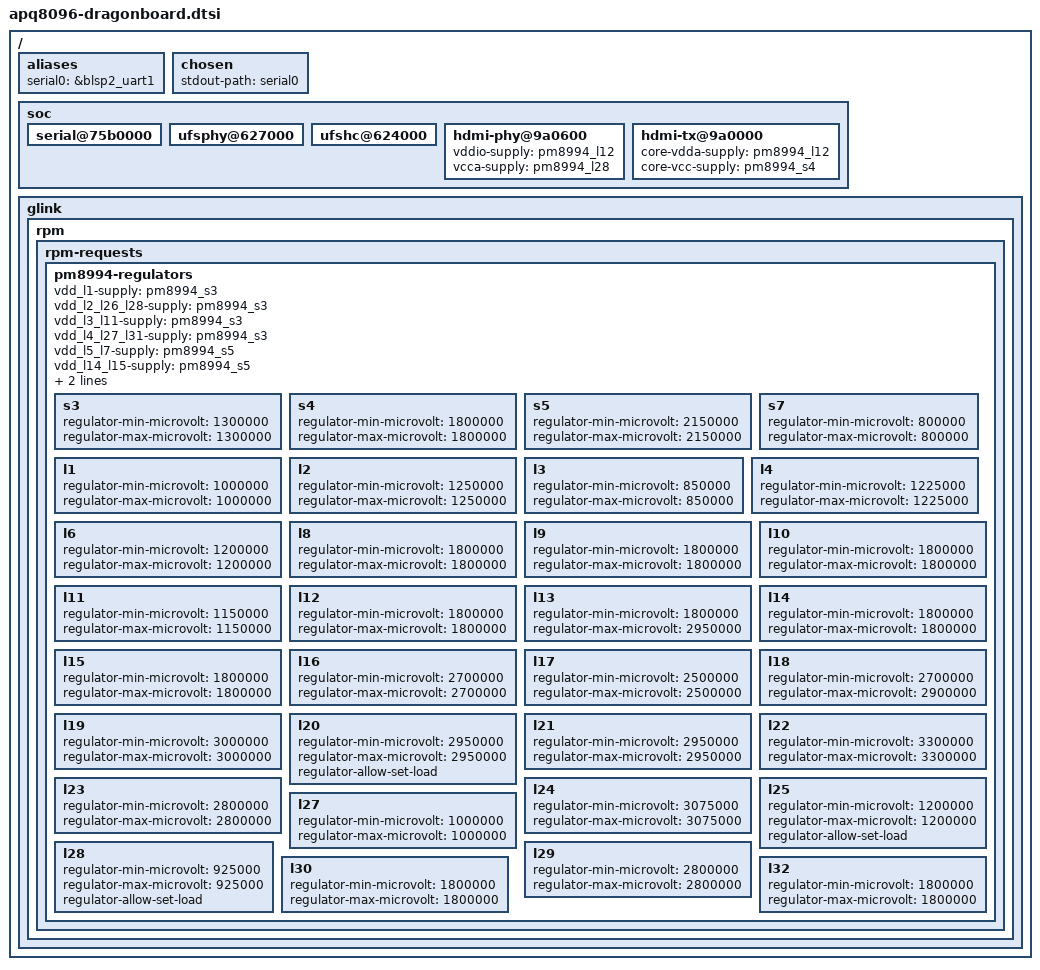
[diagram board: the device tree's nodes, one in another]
/*
 * Copyright (c) 2014-2015, The Linux Foundation. All rights reserved.
 *
 * This program is free software; you can redistribute it and/or modify
 * it under the terms of the GNU General Public License version 2 and
 * only version 2 as published by the Free Software Foundation.
 *
 * This program is distributed in the hope that it will be useful,
 * but WITHOUT ANY WARRANTY; without even the implied warranty of
 * MERCHANTABILITY or FITNESS FOR A PARTICULAR PURPOSE.  See the
 * GNU General Public License for more details.
 */

#include "msm8996.dtsi"
#include "pm8994.dtsi"

/ {
	aliases {
		serial0 = &blsp2_uart1;
	};

	chosen {
		stdout-path = "serial0";
	};

	soc {
		serial@75b0000 {
			status = "okay";
		};

		ufsphy@627000 {
			status = "okay";
		};

		ufshc@624000 {
			status = "okay";
		};

		hdmi-phy@9a0600 {
			status = "okay";

			vddio-supply = <&pm8994_l12>;
			vcca-supply = <&pm8994_l28>;
		};

		hdmi-tx@9a0000 {
			status = "okay";

			core-vdda-supply = <&pm8994_l12>;
			core-vcc-supply = <&pm8994_s4>;
		};
	};

	glink {
		rpm {
			rpm-requests {
				pm8994-regulators {
					vdd_l1-supply = <&pm8994_s3>;
					vdd_l2_l26_l28-supply = <&pm8994_s3>;
					vdd_l3_l11-supply = <&pm8994_s3>;
					vdd_l4_l27_l31-supply = <&pm8994_s3>;
					vdd_l5_l7-supply = <&pm8994_s5>;
					vdd_l14_l15-supply = <&pm8994_s5>;
					vdd_l20_l21-supply = <&pm8994_s5>;
					vdd_l25-supply = <&pm8994_s3>;

					s3 {
						regulator-min-microvolt = <1300000>;
						regulator-max-microvolt = <1300000>;
					};
					s4 {
						regulator-min-microvolt = <1800000>;
						regulator-max-microvolt = <1800000>;
					};
					s5 {
						regulator-min-microvolt = <2150000>;
						regulator-max-microvolt = <2150000>;
					};
					s7 {
						regulator-min-microvolt = <800000>;
						regulator-max-microvolt = <800000>;
					};

					l1 {
						regulator-min-microvolt = <1000000>;
						regulator-max-microvolt = <1000000>;
					};
					l2 {
						regulator-min-microvolt = <1250000>;
						regulator-max-microvolt = <1250000>;
					};
					l3 {
						regulator-min-microvolt = <850000>;
						regulator-max-microvolt = <850000>;
					};
					l4 {
						regulator-min-microvolt = <1225000>;
						regulator-max-microvolt = <1225000>;
					};
					l6 {
						regulator-min-microvolt = <1200000>;
						regulator-max-microvolt = <1200000>;
					};
					l8 {
						regulator-min-microvolt = <1800000>;
						regulator-max-microvolt = <1800000>;
					};
					l9 {
						regulator-min-microvolt = <1800000>;
						regulator-max-microvolt = <1800000>;
					};
					l10 {
						regulator-min-microvolt = <1800000>;
						regulator-max-microvolt = <1800000>;
					};
					l11 {
						regulator-min-microvolt = <1150000>;
						regulator-max-microvolt = <1150000>;
					};
					l12 {
						regulator-min-microvolt = <1800000>;
						regulator-max-microvolt = <1800000>;
					};
					l13 {
						regulator-min-microvolt = <1800000>;
						regulator-max-microvolt = <2950000>;
					};
					l14 {
						regulator-min-microvolt = <1800000>;
						regulator-max-microvolt = <1800000>;
					};
					l15 {
						regulator-min-microvolt = <1800000>;
						regulator-max-microvolt = <1800000>;
					};
					l16 {
						regulator-min-microvolt = <2700000>;
						regulator-max-microvolt = <2700000>;
					};
					l17 {
						regulator-min-microvolt = <2500000>;
						regulator-max-microvolt = <2500000>;
					};
					l18 {
						regulator-min-microvolt = <2700000>;
						regulator-max-microvolt = <2900000>;
					};
					l19 {
						regulator-min-microvolt = <3000000>;
						regulator-max-microvolt = <3000000>;
					};
					l20 {
						regulator-min-microvolt = <2950000>;
						regulator-max-microvolt = <2950000>;
						regulator-allow-set-load;
					};
					l21 {
						regulator-min-microvolt = <2950000>;
						regulator-max-microvolt = <2950000>;
					};
					l22 {
						regulator-min-microvolt = <3300000>;
						regulator-max-microvolt = <3300000>;
					};
					l23 {
						regulator-min-microvolt = <2800000>;
						regulator-max-microvolt = <2800000>;
					};
					l24 {
						regulator-min-microvolt = <3075000>;
						regulator-max-microvolt = <3075000>;
					};
					l25 {
						regulator-min-microvolt = <1200000>;
						regulator-max-microvolt = <1200000>;
						regulator-allow-set-load;
					};
					l27 {
						regulator-min-microvolt = <1000000>;
						regulator-max-microvolt = <1000000>;
					};
					l28 {
						regulator-min-microvolt = <925000>;
						regulator-max-microvolt = <925000>;
						regulator-allow-set-load;
					};
					l29 {
						regulator-min-microvolt = <2800000>;
						regulator-max-microvolt = <2800000>;
					};
					l30 {
						regulator-min-microvolt = <1800000>;
						regulator-max-microvolt = <1800000>;
					};
					l32 {
						regulator-min-microvolt = <1800000>;
						regulator-max-microvolt = <1800000>;
					};
				};
			};
		};
	};		
};
